# MCASP_0__FIFO_CFG register map
Vendor: Texas Instruments
Peripheral module from a debugger description file (folder 66AK2G0x_66AK2G1x).
Registers are 32-bit, access per field, reset 0x0 unless marked. A register's access mark holds for its fields unless they carry their own. Offsets are as the file gives them; lines under a group give offsets from that group; [hi:lo] are bit positions; {n}, {i} and the like mark numbered series; 'fields as' and 'values as' point back to an identical list; <NAME> marks a mode.

## MCASP_0__FIFO_CFG
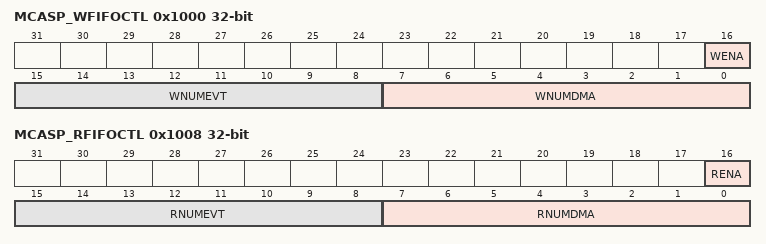
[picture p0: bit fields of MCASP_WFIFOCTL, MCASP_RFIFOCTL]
0x1000 MCASP_WFIFOCTL
  [16] WENA rw — Write FIFO enable bit. 0h (R/W) = Write FIFO is disabled. The WLVL bit in the Write FIFO status register ( 1h (R/W) = Write FIFO is enabled. If Write FIFO is to be enabled, it must be enabled prior to taking McASP out of reset.
  [15:8] WNUMEVT rw — Write word count per DMA event (32 bit). When the Write FIFO has space for at least WNUMEVT words of data, then an AXEVT (transmit DMA event) is generated to the host/DMA controller. This value should be set to a non-zero integer multiple of the number of serializers enabled as transmitters. This value must be set prior to enabling the Write FIFO. 40h = 3 to 64 words from 3h to 40h. FFh = Reserved from 41h to FFh. 0h (R/W) = 0 words 1h (R/W) = 1 word 2h (R/W) = 2 words 3h (R/W) = 3 to 64 words from 3h to 40h. 41h (R/W) = Reserved from 41h to FFh.
  [7:0] WNUMDMA rw — Write word count per transfer (32 bit words). Upon a transmit DMA event from the McASP, WNUMDMA words are transferred from the Write FIFO to the McASP. This value must equal the number of McASP serializers used as transmitters. This value must be set prior to enabling the Write FIFO. FFh = Reserved from 11h to FFh. 0h (R/W) = 0 words 1h (R/W) = 1 word 2h (R/W) = 2 words 3h (R/W) = 3-16 words from 3h to 10h. 11h (R/W) = Reserved from 11h to FFh.
0x1004 MCASP_WFIFOSTS ro
  [7:0] WLVL — Write level (read-only). Number of 32 bit words currently in the Write FIFO. 40h = 3 to 64 words currently in Write FIFO from 3h to 40h. FFh = Reserved from 41h to FFh. 0h (R/W) = 0 words currently in Write FIFO. 1h (R/W) = 1 word currently in Write FIFO. 2h (R/W) = 2 words currently in Write FIFO. 3h (R/W) = 3 to 64 words currently in Write FIFO from 3h to 40h. 41h (R/W) = Reserved from 41h to FFh.
0x1008 MCASP_RFIFOCTL
  [16] RENA rw — Read FIFO enable bit. 0h (R/W) = Read FIFO is disabled. The RLVL bit in the Read FIFO status register ( 1h (R/W) = Read FIFO is enabled. If Read FIFO is to be enabled, it must be enabled prior to taking McASP out of reset.
  [15:8] RNUMEVT rw — Read word count per DMA event (32 bit). When the Read FIFO contains at least RNUMEVT words of data, then an AREVT (receive DMA event) is generated to the host/DMA controller. This value should be set to a non-zero integer multiple of the number of serializers enabled as receivers. This value must be set prior to enabling the Read FIFO. 40h = 3 to 64 words from 3h to 40h. FFh = Reserved from 41h = FFh. 0h (R/W) = 0 words 1h (R/W) = 1 word 2h (R/W) = 2 words 3h (R/W) = 3 to 64 words from 3h to 40h. 41h (R/W) = Reserved from 41h to FFh.
  [7:0] RNUMDMA rw — Read word count per transfer (32 bit words). Upon a receive DMA event from the McASP, the Read FIFO reads RNUMDMA words from the McASP. This value must equal the number of McASP serializers used as receivers. This value must be set prior to enabling the Read FIFO. 10h = 3 to 16 words from 3h to 10h. FFh = Reserved from 11h to FFh. 0h (R/W) = 0 words 1h (R/W) = 1 word 2h (R/W) = 2 words 3h (R/W) = 3 to 16 words from 3h to 10h. 11h (R/W) = Reserved from 11h to FFh.
0x100C MCASP_RFIFOSTS ro
  [7:0] RLVL — Read level (read-only). Number of 32 bit words currently in the Read FIFO. 40h = 3 to 64 words currently in Read FIFO from 3h to 40h. FFh = Reserved from 41h to FFh. 0h (R/W) = 0 words currently in Read FIFO. 1h (R/W) = 1 word currently in Read FIFO. 2h (R/W) = 2 words currently in Read FIFO. 3h (R/W) = 3 to 64 words currently in Read FIFO from 3h to 40h. 41h (R/W) = Reserved from 41h to FFh.
